AUTOSAR XML (schema 00043)
package /vector/diag_test_app
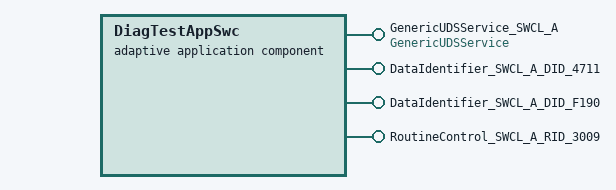
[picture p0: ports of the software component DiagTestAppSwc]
  adaptive application sw component type DiagTestAppSwc
    4 x provide port:
      GenericUDSService_SWCL_A: provided-interface=GenericUDSService
      DataIdentifier_SWCL_A_DID_4711: provided-interface=DataIdentifier_SWCL_A_DID_4711
      DataIdentifier_SWCL_A_DID_F190: provided-interface=DataIdentifier_SWCL_A_DID_F190
      RoutineControl_SWCL_A_RID_3009: provided-interface=RoutineControl_SWCL_A_RID_3009
  executable DiagTestAppExe
    root sw component prototype DiagTestAppRootSwc: application-type=DiagTestAppSwc
  adaptive autosar application DiagTestApp: category=APPLICATION_LEVEL, executable=DiagTestAppExe
